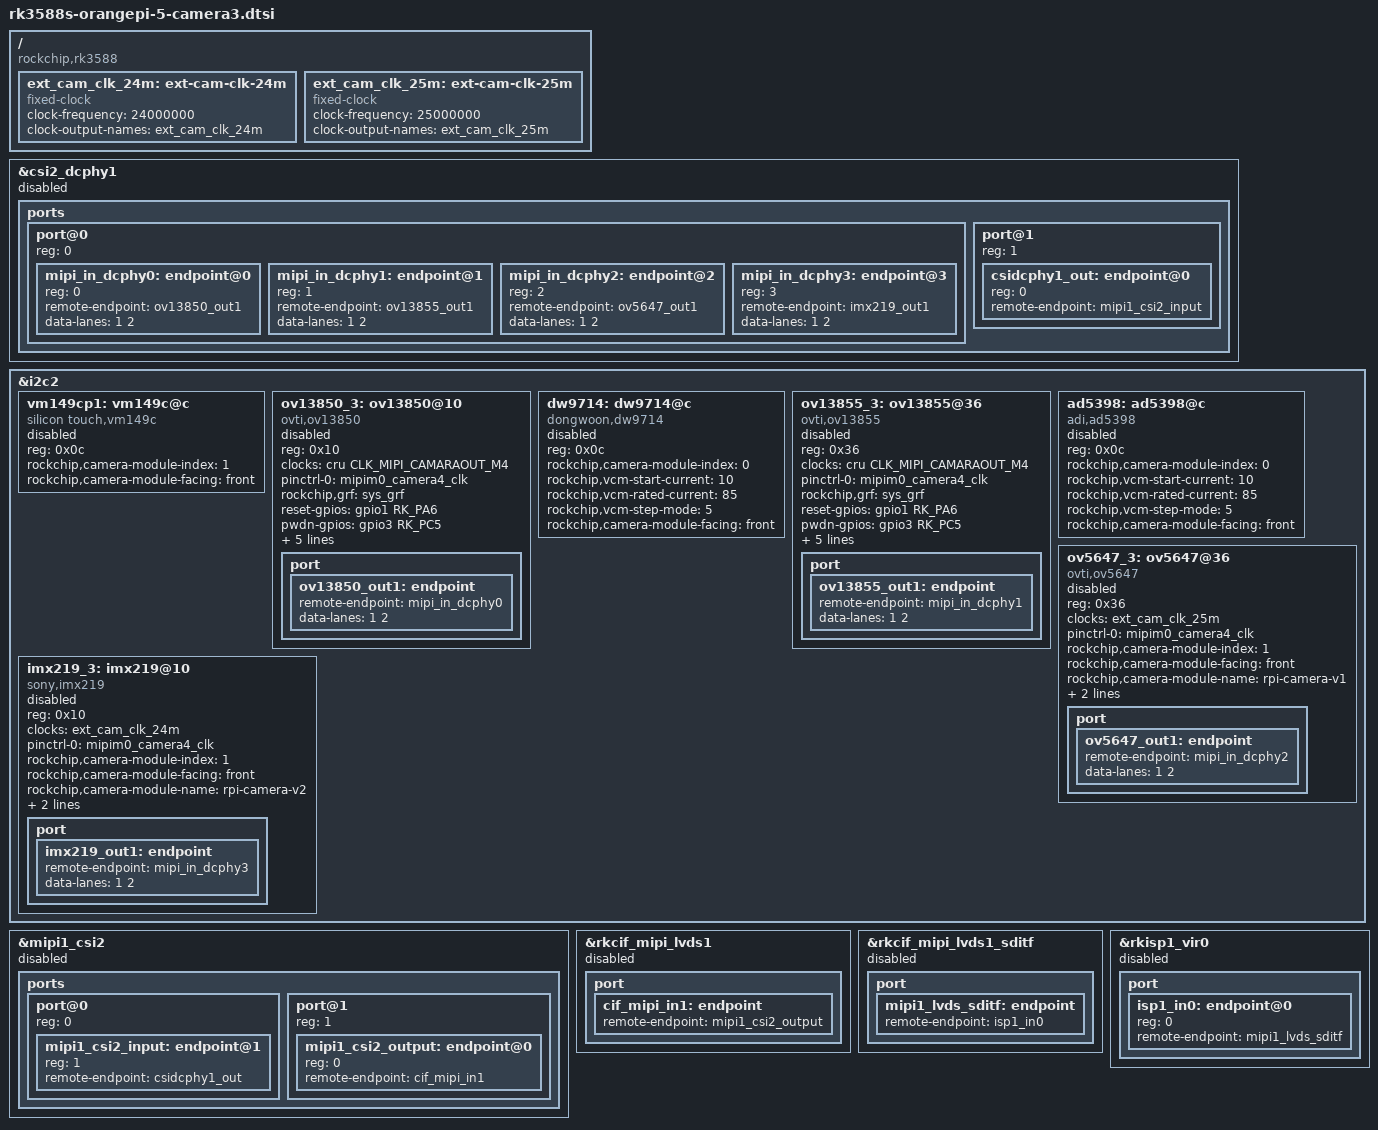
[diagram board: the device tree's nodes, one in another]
// SPDX-License-Identifier: (GPL-2.0+ OR MIT)
/*
 * Copyright (c) 2021 Rockchip Electronics Co., Ltd.
 *
 */
 
 / {
 	compatible = "rockchip,rk3588";
	ext_cam_clk_24m: ext-cam-clk-24m {
		// status = "disabled";
		compatible = "fixed-clock";
		clock-frequency = <24000000>;
		clock-output-names = "ext_cam_clk_24m";
		#clock-cells = <0>;
	};

	ext_cam_clk_25m: ext-cam-clk-25m {
		// status = "disabled";
		compatible = "fixed-clock";
		clock-frequency = <25000000>;
		clock-output-names = "ext_cam_clk_25m";
		#clock-cells = <0>;
	};
};

&csi2_dcphy1 {
	status = "disabled";

	ports {
		#address-cells = <1>;
		#size-cells = <0>;

		port@0 {
			reg = <0>;
			#address-cells = <1>;
			#size-cells = <0>;

			mipi_in_dcphy0: endpoint@0 {
				reg = <0>;
				remote-endpoint = <&ov13850_out1>;
				data-lanes = <1 2>;
			};

			mipi_in_dcphy1: endpoint@1 {
				reg = <1>;
				remote-endpoint = <&ov13855_out1>;
				data-lanes = <1 2>;
			};
			
			mipi_in_dcphy2: endpoint@2 {
				reg = <2>;
				remote-endpoint = <&ov5647_out1>;
				data-lanes = <1 2>;
			};

			mipi_in_dcphy3: endpoint@3 {
				reg = <3>;
				remote-endpoint = <&imx219_out1>;
				data-lanes = <1 2>;
			};
		};

		port@1 {
			reg = <1>;
			#address-cells = <1>;
			#size-cells = <0>;

			csidcphy1_out: endpoint@0 {
				reg = <0>;
				remote-endpoint = <&mipi1_csi2_input>;
			};
		};
	};
};

&i2c2 {
	status = "okay";

	vm149cp1: vm149c@c {
		compatible = "silicon touch,vm149c";
		status = "disabled";
		reg = <0x0c>;
		rockchip,camera-module-index = <1>;
		rockchip,camera-module-facing = "front";
	};

	ov13850_3: ov13850@10 {
		compatible = "ovti,ov13850";
		status = "disabled";
		reg = <0x10>;
		clocks = <&cru CLK_MIPI_CAMARAOUT_M4>;
		clock-names = "xvclk";
		pinctrl-names = "default";
		pinctrl-0 = <&mipim0_camera4_clk>;
		rockchip,grf = <&sys_grf>;
		reset-gpios = <&gpio1 RK_PA6 GPIO_ACTIVE_HIGH>;
		pwdn-gpios = <&gpio3 RK_PC5 GPIO_ACTIVE_HIGH>;
		rockchip,camera-module-index = <1>;
		rockchip,camera-module-facing = "front";
		rockchip,camera-module-name = "CMK-CT0116";
		rockchip,camera-module-lens-name = "default";
		lens-focus = <&vm149cp1>;
		port {
			ov13850_out1: endpoint {
				remote-endpoint = <&mipi_in_dcphy0>;
				data-lanes = <1 2>;
			};
		};
	};

	dw9714: dw9714@c {
		compatible = "dongwoon,dw9714";
		status = "disabled";
		reg = <0x0c>;
		rockchip,camera-module-index = <0>;
		rockchip,vcm-start-current = <10>;
		rockchip,vcm-rated-current = <85>;
		rockchip,vcm-step-mode = <5>;
		rockchip,camera-module-facing = "front";
	};

	ov13855_3: ov13855@36 {
		compatible = "ovti,ov13855";
		status = "disabled";
		reg = <0x36>;
		clocks = <&cru CLK_MIPI_CAMARAOUT_M4>;
		clock-names = "xvclk";
		pinctrl-names = "default";
		pinctrl-0 = <&mipim0_camera4_clk>;
		rockchip,grf = <&sys_grf>;
		reset-gpios = <&gpio1 RK_PA6 GPIO_ACTIVE_HIGH>;
		pwdn-gpios = <&gpio3 RK_PC5 GPIO_ACTIVE_HIGH>;
		rockchip,camera-module-index = <1>;
		rockchip,camera-module-facing = "front";
		rockchip,camera-module-name = "CMK-OT2016-FV1";
		rockchip,camera-module-lens-name = "default";
		lens-focus = <&dw9714>;
		port {
			ov13855_out1: endpoint {
				remote-endpoint = <&mipi_in_dcphy1>;
				data-lanes = <1 2>;
			};
		};
	};
	
	ad5398: ad5398@c {
		compatible = "adi,ad5398";
		status = "disabled";
		reg = <0x0c>;
		rockchip,camera-module-index = <0>;
		rockchip,vcm-start-current = <10>;
		rockchip,vcm-rated-current = <85>;
		rockchip,vcm-step-mode = <5>;
		rockchip,camera-module-facing = "front";
	};

	ov5647_3: ov5647@36 {
		compatible = "ovti,ov5647";
		status = "disabled";
		reg = <0x36>;
		clocks = <&ext_cam_clk_25m>;
		clock-names = "xvclk";
		pinctrl-names = "default";
		pinctrl-0 = <&mipim0_camera4_clk>;
		rockchip,camera-module-index = <1>;
		rockchip,camera-module-facing = "front";
		rockchip,camera-module-name = "rpi-camera-v1";
		rockchip,camera-module-lens-name = "default";
		lens-focus = <&ad5398>;
		port {
			ov5647_out1: endpoint {
				remote-endpoint = <&mipi_in_dcphy2>;
				data-lanes = <1 2>;
			};
		};
	};

	imx219_3: imx219@10 {
		compatible = "sony,imx219";
		status = "disabled";
		reg = <0x10>;
		clocks = <&ext_cam_clk_24m>;
		clock-names = "xvclk";
		pinctrl-names = "default";
		pinctrl-0 = <&mipim0_camera4_clk>;
		rockchip,camera-module-index = <1>;
		rockchip,camera-module-facing = "front";
		rockchip,camera-module-name = "rpi-camera-v2";
		rockchip,camera-module-lens-name = "default";
		lens-focus = <&ad5398>;
		port {
			imx219_out1: endpoint {
				remote-endpoint = <&mipi_in_dcphy3>;
				data-lanes = <1 2>;
			};
		};
	};
};

&mipi1_csi2 {
	status = "disabled";

	ports {
		#address-cells = <1>;
		#size-cells = <0>;

		port@0 {
			reg = <0>;
			#address-cells = <1>;
			#size-cells = <0>;

			mipi1_csi2_input: endpoint@1 {
				reg = <1>;
				remote-endpoint = <&csidcphy1_out>;
			};
		};

		port@1 {
			reg = <1>;
			#address-cells = <1>;
			#size-cells = <0>;

			mipi1_csi2_output: endpoint@0 {
				reg = <0>;
				remote-endpoint = <&cif_mipi_in1>;
			};
		};
	};
};

&rkcif_mipi_lvds1 {
	status = "disabled";

	port {
		cif_mipi_in1: endpoint {
			remote-endpoint = <&mipi1_csi2_output>;
		};
	};
};

&rkcif_mipi_lvds1_sditf {
	status = "disabled";

        port {
                mipi1_lvds_sditf: endpoint {
                        remote-endpoint = <&isp1_in0>;
                };
        };
};

&rkisp1_vir0 {
	status = "disabled";

	port {
		#address-cells = <1>;
		#size-cells = <0>;

		isp1_in0: endpoint@0 {
			reg = <0>;
			remote-endpoint = <&mipi1_lvds_sditf>;
		};
	};
};
